VERSION "AGL Virtual Car 1.0"

BS_:

BO_ 1001 Vehicle_Status_1: 8 Vector_XXX
  SG_ PT_VehicleAvgSpeed : 7|15@0+ (0.015625,0) [0|0] "" Vector_XXX

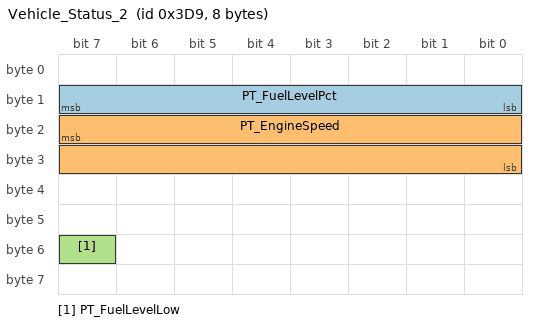
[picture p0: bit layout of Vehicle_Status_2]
BO_ 985 Vehicle_Status_2: 8 Vector_XXX
  SG_ PT_FuelLevelPct : 8|8@1+ (0.392157,0) [0|0] "" Vector_XXX
  SG_ PT_EngineSpeed : 23|16@0+ (0.25,0) [0|0] "" Vector_XXX
  SG_ PT_FuelLevelLow : 55|1@1+ (1,0) [0|1] "" Vector_XXX

BO_ 33 Steering_Wheel: 8 Vector_XXX
  SG_ SW_Previous : 39|1@1+ (1,0) [0|1] "" Vector_XXX
  SG_ SW_VolumeUp : 38|1@1+ (1,0) [0|1] "" Vector_XXX
  SG_ SW_Mode : 37|1@1+ (1,0) [0|1] "" Vector_XXX
  SG_ SW_VolumeDown : 36|1@1+ (1,0) [0|1] "" Vector_XXX
  SG_ SW_Next : 35|1@1+ (1,0) [0|1] "" Vector_XXX
  SG_ SW_Info : 33|1@1+ (1,0) [0|1] "" Vector_XXX
  SG_ SW_VolumeMute : 32|1@1+ (1,0) [0|1] "" Vector_XXX
  SG_ SW_Voice : 42|1@1+ (1,0) [0|1] "" Vector_XXX
  SG_ SW_PhoneHangup : 41|1@1+ (1,0) [0|1] "" Vector_XXX
  SG_ SW_PhoneCall : 40|1@1+ (1,0) [0|1] "" Vector_XXX
  SG_ SW_CruiseEnable : 55|1@1+ (1,0) [0|1] "" Vector_XXX
  SG_ SW_CruiseResume : 54|1@1+ (1,0) [0|1] "" Vector_XXX
  SG_ SW_CruiseSet : 52|1@1+ (1,0) [0|1] "" Vector_XXX
  SG_ SW_CruiseCancel : 51|1@1+ (1,0) [0|1] "" Vector_XXX
  SG_ SW_CruiseLimit : 49|1@1+ (1,0) [0|1] "" Vector_XXX
  SG_ SW_CruiseDistance : 48|1@1+ (1,0) [0|1] "" Vector_XXX
  SG_ SW_Horn : 63|1@1+ (1,0) [0|1] "" Vector_XXX
  SG_ SW_LaneDepartureWarning : 56|1@1+ (1,0) [0|1] "" Vector_XXX
